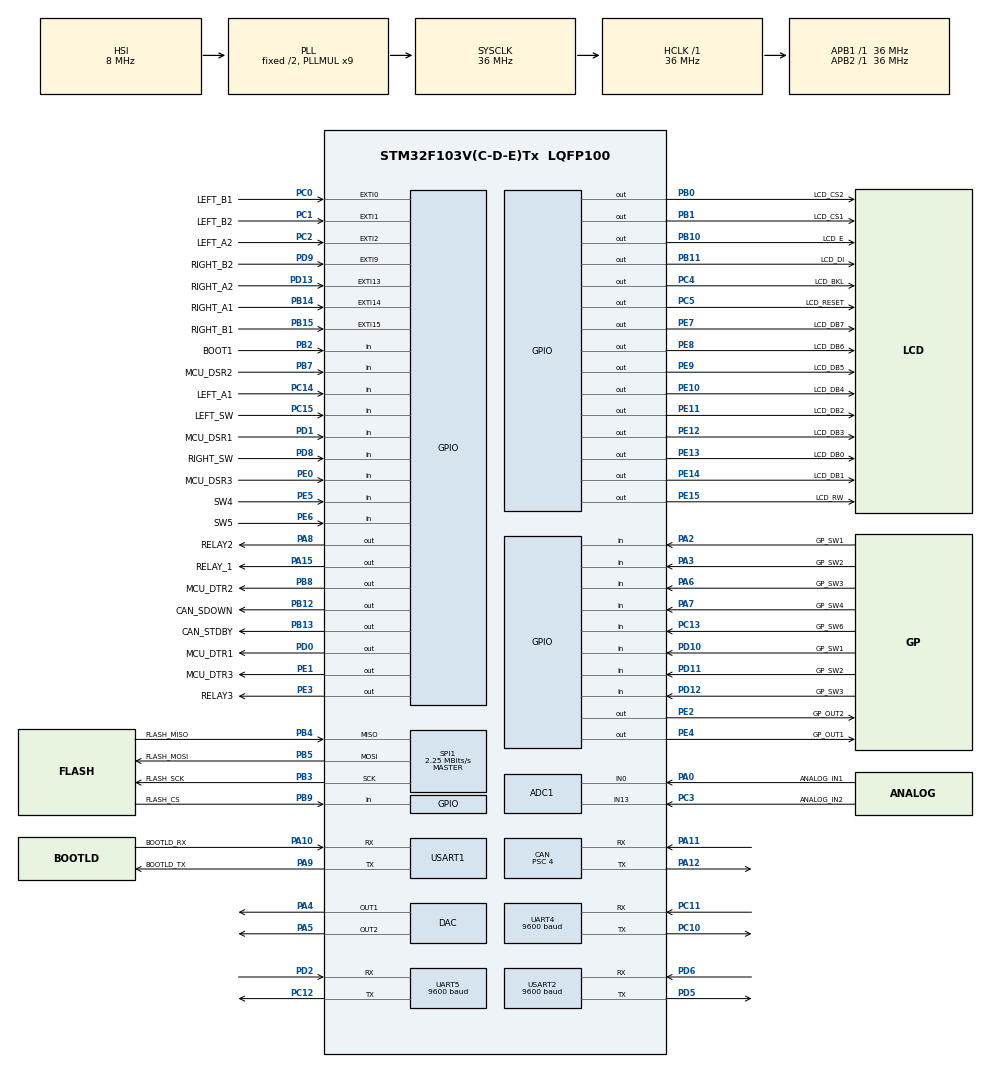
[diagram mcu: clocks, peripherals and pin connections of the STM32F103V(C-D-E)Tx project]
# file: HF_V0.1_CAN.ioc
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ADC1.Channel-0\#ChannelRegularConversion=ADC_CHANNEL_13
ADC1.NbrOfConversionFlag=1
ADC1.Rank-0\#ChannelRegularConversion=1
ADC1.SamplingTime-0\#ChannelRegularConversion=ADC_SAMPLETIME_1CYCLE_5
ADC1.master=1
CAN.BS1=CAN_BS1_15TQ
CAN.BS2=CAN_BS2_2TQ
CAN.CalculateBaudRate=500000
CAN.CalculateTimeBit=2000
CAN.CalculateTimeQuantum=111.11111111111111
CAN.Prescaler=4
FREERTOS.Tasks01=defaultTask,24,128,StartDefaultTask,Default,NULL,Dynamic,NULL,NULL
FREERTOS.configTOTAL_HEAP_SIZE=15000
FREERTOS.configUSE_NEWLIB_REENTRANT=1
Mcu.Family=STM32F1
Mcu.Name=STM32F103V(C-D-E)Tx
Mcu.Package=LQFP100
NVIC.EXTI0_IRQn=true\:5\:0\:false\:false\:true\:true\:true\:true\:true
NVIC.EXTI15_10_IRQn=true\:5\:0\:false\:false\:true\:true\:true\:true\:true
NVIC.EXTI1_IRQn=true\:5\:0\:false\:false\:true\:true\:true\:true\:true
NVIC.EXTI2_IRQn=true\:5\:0\:false\:false\:true\:true\:true\:true\:true
NVIC.EXTI9_5_IRQn=true\:5\:0\:false\:false\:true\:true\:true\:true\:true
NVIC.PriorityGroup=NVIC_PRIORITYGROUP_4
NVIC.TIM3_IRQn=true\:10\:0\:true\:false\:true\:true\:true\:true\:true
NVIC.TIM6_IRQn=true\:15\:0\:false\:false\:true\:false\:false\:true\:true
NVIC.TimeBase=TIM6_IRQn
NVIC.TimeBaseIP=TIM6
NVIC.UART4_IRQn=true\:15\:0\:true\:false\:true\:true\:true\:true\:true
NVIC.UART5_IRQn=true\:15\:0\:true\:false\:true\:true\:true\:true\:true
NVIC.USART1_IRQn=true\:5\:0\:false\:false\:true\:true\:true\:true\:true
NVIC.USART2_IRQn=true\:5\:0\:false\:false\:true\:true\:true\:true\:true
NVIC.USB_LP_CAN1_RX0_IRQn=true\:5\:0\:false\:false\:true\:true\:true\:true\:true
PA0-WKUP.GPIO_Label=ANALOG_IN1
PA0-WKUP.Signal=ADCx_IN0
PA10.GPIO_Label=BOOTLD_RX
PA10.Mode=Asynchronous
PA10.Signal=USART1_RX
PA11.Mode=CAN_Activate
PA11.Signal=CAN_RX
PA12.Mode=CAN_Activate
PA12.Signal=CAN_TX
PA13.Mode=Serial_Wire
PA13.Signal=SYS_JTMS-SWDIO
PA14.Mode=Serial_Wire
PA14.Signal=SYS_JTCK-SWCLK
PA15.GPIO_Label=RELAY_1
PA15.Signal=GPIO_Output
PA2.GPIO_Label=GP_SW1
PA2.Signal=GPIO_Input
PA3.GPIO_Label=GP_SW2
PA3.Signal=GPIO_Input
PA4.Signal=COMP_DAC1_group
PA5.Signal=COMP_DAC2_group
PA6.GPIO_Label=GP_SW3
PA6.Signal=GPIO_Input
PA7.GPIO_Label=GP_SW4
PA7.Signal=GPIO_Input
PA8.GPIO_Label=RELAY2
PA8.Signal=GPIO_Output
PA9.GPIO_Label=BOOTLD_TX
PA9.Mode=Asynchronous
PA9.Signal=USART1_TX
PB0.GPIO_Label=LCD_CS2
PB0.Signal=GPIO_Output
PB1.GPIO_Label=LCD_CS1
PB1.Signal=GPIO_Output
PB10.GPIO_Label=LCD_E
PB10.Signal=GPIO_Output
PB11.GPIO_Label=LCD_DI
PB11.Signal=GPIO_Output
PB12.GPIO_Label=CAN_SDOWN
PB12.Signal=GPIO_Output
PB13.GPIO_Label=CAN_STDBY
PB13.Signal=GPIO_Output
PB14.GPIO_Label=RIGHT_A1
PB14.Signal=GPXTI14
PB15.GPIO_Label=RIGHT_B1
PB15.Signal=GPXTI15
PB2.GPIO_Label=BOOT1
PB2.Signal=GPIO_Input
PB3.GPIO_Label=FLASH_SCK
PB3.Mode=Full_Duplex_Master
PB3.Signal=SPI1_SCK
PB4.GPIO_Label=FLASH_MISO
PB4.Mode=Full_Duplex_Master
PB4.Signal=SPI1_MISO
PB5.GPIO_Label=FLASH_MOSI
PB5.Mode=Full_Duplex_Master
PB5.Signal=SPI1_MOSI
PB7.GPIO_Label=MCU_DSR2
PB7.Signal=GPIO_Input
PB8.GPIO_Label=MCU_DTR2
PB8.Signal=GPIO_Output
PB9.GPIO_Label=FLASH_CS
PB9.Signal=GPIO_Input
PC0.GPIO_Label=LEFT_B1
PC0.Signal=GPXTI0
PC1.GPIO_Label=LEFT_B2
PC1.Signal=GPXTI1
PC10.Mode=Asynchronous
PC10.Signal=UART4_TX
PC11.Mode=Asynchronous
PC11.Signal=UART4_RX
PC12.Mode=Asynchronous
PC12.Signal=UART5_TX
PC13-TAMPER-RTC.GPIO_Label=GP_SW6
PC13-TAMPER-RTC.Signal=GPIO_Input
PC14-OSC32_IN.GPIO_Label=LEFT_A1
PC14-OSC32_IN.Signal=GPIO_Input
PC15-OSC32_OUT.GPIO_Label=LEFT_SW
PC15-OSC32_OUT.Signal=GPIO_Input
PC2.GPIO_Label=LEFT_A2
PC2.Signal=GPXTI2
PC3.GPIO_Label=ANALOG_IN2
PC3.Signal=ADCx_IN13
PC4.GPIO_Label=LCD_BKL
PC4.Signal=GPIO_Output
PC5.GPIO_Label=LCD_RESET
PC5.Signal=GPIO_Output
PD0.GPIO_Label=MCU_DTR1
PD0.Signal=GPIO_Output
PD1.GPIO_Label=MCU_DSR1
PD1.Signal=GPIO_Input
PD10.GPIO_Label=GP_SW1
PD10.Signal=GPIO_Input
PD11.GPIO_Label=GP_SW2
PD11.Signal=GPIO_Input
PD12.GPIO_Label=GP_SW3
PD12.Signal=GPIO_Input
PD13.GPIO_Label=RIGHT_A2
PD13.Signal=GPXTI13
PD2.Mode=Asynchronous
PD2.Signal=UART5_RX
PD5.Mode=Asynchronous
PD5.Signal=USART2_TX
PD6.Mode=Asynchronous
PD6.Signal=USART2_RX
PD8.GPIO_Label=RIGHT_SW
PD8.Signal=GPIO_Input
PD9.GPIO_Label=RIGHT_B2
PD9.Signal=GPXTI9
PE0.GPIO_Label=MCU_DSR3
PE0.Signal=GPIO_Input
PE1.GPIO_Label=MCU_DTR3
PE1.Signal=GPIO_Output
PE10.GPIO_Label=LCD_DB4
PE10.Signal=GPIO_Output
PE11.GPIO_Label=LCD_DB2
PE11.Signal=GPIO_Output
PE12.GPIO_Label=LCD_DB3
PE12.Signal=GPIO_Output
PE13.GPIO_Label=LCD_DB0
PE13.Signal=GPIO_Output
PE14.GPIO_Label=LCD_DB1
PE14.Signal=GPIO_Output
PE15.GPIO_Label=LCD_RW
PE15.Signal=GPIO_Output
PE2.GPIO_Label=GP_OUT2
PE2.Signal=GPIO_Output
PE3.GPIO_Label=RELAY3
PE3.Signal=GPIO_Output
PE4.GPIO_Label=GP_OUT1
PE4.Signal=GPIO_Output
PE5.GPIO_Label=SW4
PE5.Signal=GPIO_Input
PE6.GPIO_Label=SW5
PE6.Signal=GPIO_Input
PE7.GPIO_Label=LCD_DB7
PE7.Signal=GPIO_Output
PE8.GPIO_Label=LCD_DB6
PE8.Signal=GPIO_Output
PE9.GPIO_Label=LCD_DB5
PE9.Signal=GPIO_Output
ProjectManager.HeapSize=0x200
ProjectManager.StackSize=0x400
ProjectManager.TargetToolchain=STM32CubeIDE
RCC.ADCPresc=RCC_ADCPCLK2_DIV4
RCC.AHBFreq_Value=36000000
RCC.APB1Freq_Value=36000000
RCC.APB1TimFreq_Value=36000000
RCC.APB2Freq_Value=36000000
RCC.APB2TimFreq_Value=36000000
RCC.HCLKFreq_Value=36000000
RCC.PLLMUL=RCC_PLL_MUL9
RCC.SYSCLKFreq_VALUE=36000000
RCC.SYSCLKSource=RCC_SYSCLKSOURCE_PLLCLK
RCC.USBFreq_Value=36000000
SH.ADCx_IN0.0=ADC1_IN0,IN0
SH.ADCx_IN13.0=ADC1_IN13,IN13
SH.COMP_DAC1_group.0=DAC_OUT1,DAC_OUT1
SH.COMP_DAC2_group.0=DAC_OUT2,DAC_OUT2
SPI1.BaudRatePrescaler=SPI_BAUDRATEPRESCALER_16
SPI1.CalculateBaudRate=2.25 MBits/s
SPI1.Direction=SPI_DIRECTION_2LINES
SPI1.Mode=SPI_MODE_MASTER
SPI1.VirtualType=VM_MASTER
TIM3.Period=49999
TIM3.Prescaler=3599
UART4.BaudRate=9600
UART4.VirtualMode=Asynchronous
UART5.BaudRate=9600
UART5.VirtualMode=Asynchronous
USART1.VirtualMode=VM_ASYNC
USART2.BaudRate=9600
USART2.VirtualMode=VM_ASYNC
VP_FREERTOS_VS_CMSIS_V2.Mode=CMSIS_V2
VP_SYS_VS_tim6.Mode=TIM6
VP_TIM3_VS_ClockSourceINT.Mode=Internal
board=custom

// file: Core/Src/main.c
/* USER CODE BEGIN Header */
/**
 ******************************************************************************
 * @file           : main.c
 * @brief          : Main program body
 ******************************************************************************
 * @attention
 *
 * Copyright (c) 2024 STMicroelectronics.
 * All rights reserved.
 *
 * This software is licensed under terms that can be found in the LICENSE file
 * in the root directory of this software component.
 * If no LICENSE file comes with this software, it is provided AS-IS.
 *
 ******************************************************************************
 */
#define FREERTOS
/* USER CODE END Header */
#include "main.h"
#include "cmsis_os.h"
#include "adc.h"
#include "can.h"
#include "dac.h"
#include "spi.h"
#include "tim.h"
#include "usart.h"
#include "gpio.h"

/* USER CODE BEGIN Includes */
#include "..\LCD\glcd.h"
#include "global_vars.h"
/* USER CODE END Includes */

void SystemClock_Config(void);
void MX_FREERTOS_Init(void);

int main(void)
{

  /* MCU Configuration--------------------------------------------------------*/

  /* Reset of all peripherals, Initializes the Flash interface and the Systick. */
  HAL_Init();

  /* Configure the system clock */
  SystemClock_Config();

  /* Initialize all configured peripherals */
  MX_GPIO_Init();
  MX_ADC1_Init();
  MX_CAN_Init();
  MX_DAC_Init();
  MX_SPI1_Init();
  MX_UART4_Init();
  MX_UART5_Init();
  MX_USART1_UART_Init();
  MX_USART2_UART_Init();
  MX_TIM3_Init();

  CAN_Filter_Config();

  if(HAL_CAN_ActivateNotification(&hcan,CAN_IT_RX_FIFO0_MSG_PENDING)!=HAL_OK)
  {
	  Error_Handler();
  }

  if(HAL_CAN_Start(&hcan)!=HAL_OK)
  {
	  Error_Handler();
  }

  /* USER CODE BEGIN 2 */

#ifndef FREERTOS
  /* USER CODE END 2 */

  /* Init scheduler */
  osKernelInitialize();

  /* Call init function for freertos objects (in cmsis_os2.c) */
  MX_FREERTOS_Init();

  /* Start scheduler */
  osKernelStart();

  /* We should never get here as control is now taken by the scheduler */

  /* Infinite loop */
  /* USER CODE BEGIN WHILE */
#else
	/* Call initialize function for free-rtos objects (in cmsis_os2.c) */
	MX_FREERTOS_Init();
#endif
	while (1)
	{
    /* USER CODE END WHILE */

	}
}

void SystemClock_Config(void)
{
  RCC_OscInitTypeDef RCC_OscInitStruct = {0};
  RCC_ClkInitTypeDef RCC_ClkInitStruct = {0};
  RCC_PeriphCLKInitTypeDef PeriphClkInit = {0};

  /** Initializes the RCC Oscillators according to the specified parameters
  * in the RCC_OscInitTypeDef structure.
  */
  RCC_OscInitStruct.OscillatorType = RCC_OSCILLATORTYPE_HSI;
  RCC_OscInitStruct.HSIState = RCC_HSI_ON;
  RCC_OscInitStruct.HSICalibrationValue = RCC_HSICALIBRATION_DEFAULT;
  RCC_OscInitStruct.PLL.PLLState = RCC_PLL_ON;
  RCC_OscInitStruct.PLL.PLLSource = RCC_PLLSOURCE_HSI_DIV2;
  RCC_OscInitStruct.PLL.PLLMUL = RCC_PLL_MUL9;
  if (HAL_RCC_OscConfig(&RCC_OscInitStruct) != HAL_OK)
  {
    Error_Handler();
  }

  /** Initializes the CPU, AHB and APB buses clocks
  */
  RCC_ClkInitStruct.ClockType = RCC_CLOCKTYPE_HCLK|RCC_CLOCKTYPE_SYSCLK
                              |RCC_CLOCKTYPE_PCLK1|RCC_CLOCKTYPE_PCLK2;
  RCC_ClkInitStruct.SYSCLKSource = RCC_SYSCLKSOURCE_PLLCLK;
  RCC_ClkInitStruct.AHBCLKDivider = RCC_SYSCLK_DIV1;
  RCC_ClkInitStruct.APB1CLKDivider = RCC_HCLK_DIV1;
  RCC_ClkInitStruct.APB2CLKDivider = RCC_HCLK_DIV1;

  if (HAL_RCC_ClockConfig(&RCC_ClkInitStruct, FLASH_LATENCY_1) != HAL_OK)
  {
    Error_Handler();
  }
  PeriphClkInit.PeriphClockSelection = RCC_PERIPHCLK_ADC;
  PeriphClkInit.AdcClockSelection = RCC_ADCPCLK2_DIV4;
  if (HAL_RCCEx_PeriphCLKConfig(&PeriphClkInit) != HAL_OK)
  {
    Error_Handler();
  }
}

void Error_Handler(void)
{
	__disable_irq();
	while (1)
	{
	}
}
